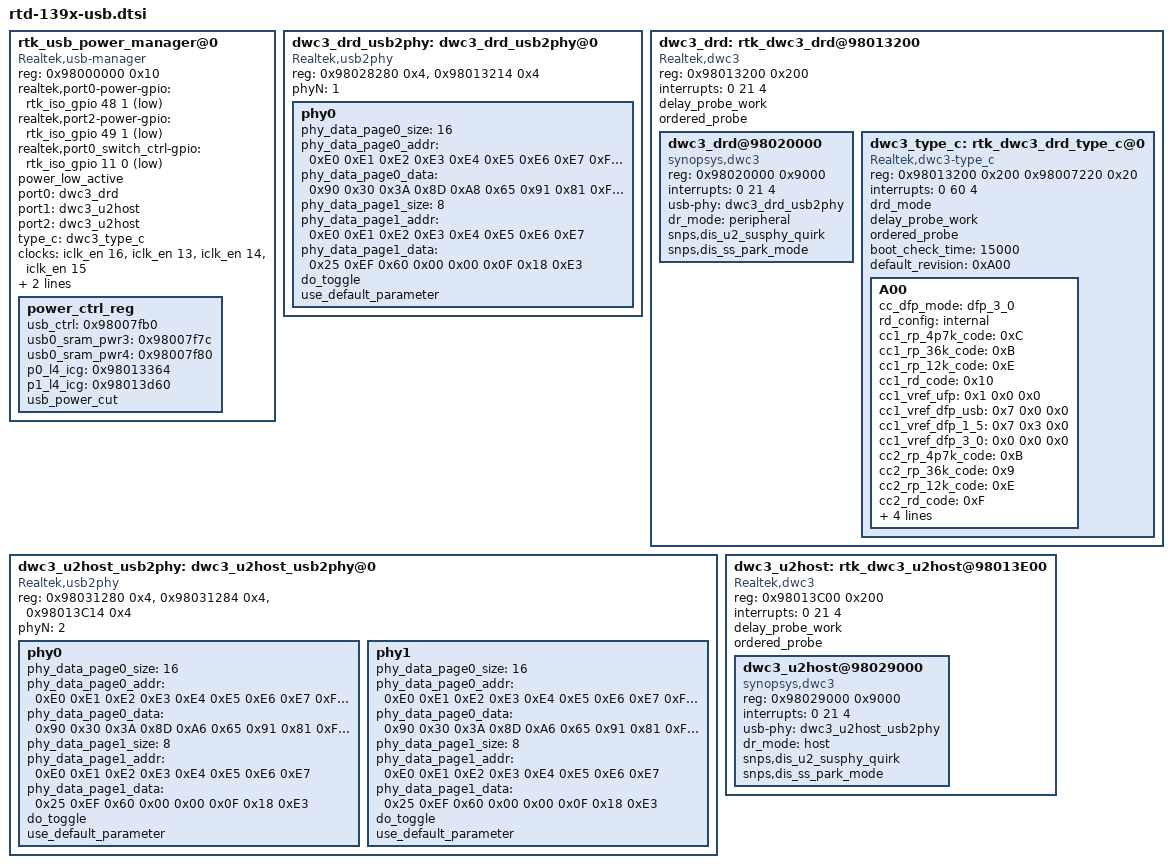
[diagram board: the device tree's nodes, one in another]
/*
 * realtek,type_c-power-gpio: TypeC power, output, default low
 * realtek,u2host-power-gpio: ehci and u2host power, output, default low
 * realtek,u3host-power-gpio: 1296 u3host power, output, default low
 *
 * usb_iso_mode: ISO mode is only port suspend (Default disable)
 * usb_power_cut: Non ISO mode and power cut (Default disable power cut)
 * Note if enable ISO mode, then power_cut will not effective
 */

	rtk_usb_power_manager@0 {
		compatible = "Realtek,usb-manager";
		reg = <0x98000000 0x10>;
		realtek,port0-power-gpio = <&rtk_iso_gpio 48 1 3>;
		//realtek,port1-power-gpio = <&rtk_iso_gpio 49 1 1>;
		realtek,port2-power-gpio = <&rtk_iso_gpio 49 1 3>;
		realtek,port0_switch_ctrl-gpio = <&rtk_iso_gpio 11 0 1>;
		power_low_active;

		port0 = <&dwc3_drd>;
		port1 = <&dwc3_u2host>;
		port2 = <&dwc3_u2host>;
		type_c = <&dwc3_type_c>;

		//usb_iso_mode;  /* ISO mode is only port suspend (Default disable) */
		//en_usb_storage_reprobe; /* To enable usb storage re-probe*/
		//rescue_usb; /* For rescue dtb use */

		clocks = <&iclk_en 16>, /* clk_en_usb */
			<&iclk_en 13>,  /* clk_en_usb_drd */
			<&iclk_en 14>,  /* clk_en_usb_host_0 */
			<&iclk_en 15>;  /* clk_en_usb_host_1 */
		clock-names = "clk_en_usb", /*clk_en_usb*/
			"clk_en_phy0_to_host", /*clk_en_usb_drd*/
			"clk_en_phy1_to_host", /*clk_en_usb_host_0*/
			"clk_en_phy2_to_host"; /*clk_en_usb_host_1*/

		resets =
			<&iasr 0x100>,
			<&irst 14>, /* rstn_usb_drd */
			<&irst 15>, /* rstn_usb_host */
			<&iasr 16>, /* rstn_usb_phy_0 */
			<&iasr 17>, /* rstn_usb_phy_1 */
			<&iasr 18>, /* rstn_usb_phy_2 */
			<&irst 19>, /* rstn_usb */
			<&irst 20>; /* rstn_type_c */

		reset-names = "apply",
			"usb_host0", /*rstn_usb_drd*/
			"usb_host1", /*rstn_usb_host*/
			"u2phy0", /*rstn_usb_phy_0*/
			"u2phy1", /*rstn_usb_phy_1*/
			"u2phy2", /*rstn_usb_phy_2*/
			"usb", /*rstn_usb*/
			"type_c"; /*rstn_type_c*/

		power_ctrl_reg {
			usb_ctrl = <0x98007fb0>;
			/* Port 0~2 */
			usb0_sram_pwr3 = <0x98007f7c>;
			usb0_sram_pwr4 = <0x98007f80>;

			/* l4_icg */
			p0_l4_icg = <0x98013364>;
			p1_l4_icg = <0x98013d60>;

			usb_power_cut; /* Non ISO mode and power cut (Default disable power cut) */
			               /* Note if enable ISO mode, then power_cut will not effective*/
		};

	};

	dwc3_drd_usb2phy: dwc3_drd_usb2phy@0 {
		compatible = "Realtek,usb2phy";
		reg = <0x98028280 0x4>, <0x98013214 0x4>;
		#address-cells = <1>;
		#size-cells = <1>;
		ranges;
		phyN = <1>;
		phy0 {
			phy_data_page0_size = <16>;
			phy_data_page0_addr = /bits/ 8
				<0xE0 0xE1 0xE2 0xE3 0xE4 0xE5 0xE6 0xE7 0xF0 0xF1
				0xF2 0xF3 0xF4 0xF5 0xF6 0xF7>;
			phy_data_page0_data = /bits/ 8
				<0x90 0x30 0x3A 0x8D 0xA8 0x65 0x91 0x81 0xFC 0x8C
				0x00 0x11 0x9B 0x81 0x00 0x02>;
			phy_data_page1_size = <8>;
			phy_data_page1_addr = /bits/ 8
				<0xE0 0xE1 0xE2 0xE3 0xE4 0xE5 0xE6 0xE7>;
			phy_data_page1_data = /bits/ 8
				<0x25 0xEF 0x60 0x00 0x00 0x0F 0x18 0xE3>;
			do_toggle;
			//check_efuse;
			use_default_parameter;
		};
	};

	dwc3_drd: rtk_dwc3_drd@98013200 {
		compatible = "Realtek,dwc3";
		reg = <0x98013200 0x200>;
		interrupts = <0 21 4>;
		#address-cells = <1>;
		#size-cells = <1>;
		ranges;
		delay_probe_work; //To delay probe work
		ordered_probe; // ordered probe in delay work
		status = "okay";

		dwc3_drd@98020000 {
			compatible = "synopsys,dwc3";
			reg = <0x98020000 0x9000>;
			interrupts = <0 21 4>;
			usb-phy = <&dwc3_drd_usb2phy>;
			dr_mode = "peripheral"; /*otg, host, peripheral*/
			//tx-fifo-resize;
			snps,dis_u2_susphy_quirk; // Add workaround for Usb3.0 hub suspend
			snps,dis_ss_park_mode; // disable usb3.0 park mode
		};

		dwc3_type_c: rtk_dwc3_drd_type_c@0 {
			compatible = "Realtek,dwc3-type_c";
			reg = <0x98013200 0x200 0x98007220 0x20>;
			interrupts = <0 60 4>;
			drd_mode;  /*depend on dwc3 dr_mode = "peripheral"*/
			//debug; /*to enable debug log*/
			delay_probe_work; /*To delay probe work*/
			ordered_probe; /*ordered probe in delay work*/
			boot_check_time = <15000>; /*ms (At boot Device switch Host time)*/

			default_revision = <0xA00>;
			A00 {
				cc_dfp_mode = "dfp_3_0"; /*dfp_3_0, dfp_1_5, dfp_usb*/
				rd_config = "internal"; /*internal, extrenal*/
				cc1_rp_4p7k_code = <0xC>;
				cc1_rp_36k_code = <0xB>;
				cc1_rp_12k_code = <0xE>;
				cc1_rd_code = <0x10>; /*for internal rd*/
				cc1_vref_ufp = /bits/ 8
					<0x1 0x0 0x0>; /*<1p23v,0p66v,0p2v>*/
				cc1_vref_dfp_usb = /bits/ 8
					<0x7 0x0 0x0>; /*<0_1p6v,0p2v,unused>*/
				cc1_vref_dfp_1_5 = /bits/ 8
					<0x7 0x3 0x0>; /*<1_1p6v,0p4v,0p2v>*/
				cc1_vref_dfp_3_0 = /bits/ 8
					<0x0 0x0 0x0>; /*<2p6v,0p8v,0p2v>*/
				cc2_rp_4p7k_code = <0xB>;
				cc2_rp_36k_code = <0x9>;
				cc2_rp_12k_code = <0xE>;
				cc2_rd_code = <0xF>; /*for internal rd*/
				cc2_vref_ufp = /bits/ 8
					<0x3 0x2 0x2>; /*<1p23v,0p66v,0p2v>*/
				cc2_vref_dfp_usb = /bits/ 8
					<0x7 0x2 0x0>; /*<0_1p6v,0p2v,unused>*/
				cc2_vref_dfp_1_5 = /bits/ 8
					<0x7 0x3 0x2>; /*<1_1p6v,0p4v,0p2v>*/
				cc2_vref_dfp_3_0 = /bits/ 8
					<0x1 0x3 0x2>; /*<2p6v,0p8v,0p2v>*/
			};
		};
	};

	dwc3_u2host_usb2phy: dwc3_u2host_usb2phy@0 {
		compatible = "Realtek,usb2phy";
		reg = <0x98031280 0x4>, <0x98031284 0x4>, <0x98013C14 0x4>;
		#address-cells = <1>;
		#size-cells = <1>;
		ranges;
		phyN = <2>;
		phy0 {
			phy_data_page0_size = <16>;
			phy_data_page0_addr = /bits/ 8
				<0xE0 0xE1 0xE2 0xE3 0xE4 0xE5 0xE6 0xE7 0xF0 0xF1
				0xF2 0xF3 0xF4 0xF5 0xF6 0xF7>;
			phy_data_page0_data = /bits/ 8
				<0x90 0x30 0x3A 0x8D 0xA6 0x65 0x91 0x81 0xFC 0x8C
				0x00 0x11 0x9B 0x81 0x00 0x02>;
			phy_data_page1_size = <8>;
			phy_data_page1_addr = /bits/ 8
				<0xE0 0xE1 0xE2 0xE3 0xE4 0xE5 0xE6 0xE7>;
			phy_data_page1_data = /bits/ 8
			<0x25 0xEF 0x60 0x00 0x00 0x0F 0x18 0xE3>;
			do_toggle;
			//check_efuse;
			use_default_parameter;
		};
		phy1 {
			phy_data_page0_size = <16>;
			phy_data_page0_addr = /bits/ 8
				<0xE0 0xE1 0xE2 0xE3 0xE4 0xE5 0xE6 0xE7 0xF0 0xF1
				0xF2 0xF3 0xF4 0xF5 0xF6 0xF7>;
			phy_data_page0_data = /bits/ 8
				<0x90 0x30 0x3A 0x8D 0xA6 0x65 0x91 0x81 0xFC 0x8C
				0x00 0x11 0x9B 0x81 0x00 0x02>;
			phy_data_page1_size = <8>;
			phy_data_page1_addr = /bits/ 8
				<0xE0 0xE1 0xE2 0xE3 0xE4 0xE5 0xE6 0xE7>;
			phy_data_page1_data = /bits/ 8
			<0x25 0xEF 0x60 0x00 0x00 0x0F 0x18 0xE3>;
			do_toggle;
			//check_efuse;
			use_default_parameter;
		};
	};

	dwc3_u2host: rtk_dwc3_u2host@98013E00 {
		compatible = "Realtek,dwc3";
		reg = <0x98013C00 0x200>;
		interrupts = <0 21 4>;
		#address-cells = <1>;
		#size-cells = <1>;
		ranges;
		delay_probe_work; //To delay probe work
		ordered_probe; // ordered probe in delay work
		status = "okay";

		dwc3_u2host@98029000 {
			compatible = "synopsys,dwc3";
			reg = <0x98029000 0x9000>;
			interrupts = <0 21 4>;
			usb-phy = <&dwc3_u2host_usb2phy>;
			dr_mode = "host"; /*only host*/
			//tx-fifo-resize;
			snps,dis_u2_susphy_quirk; // Add workaround for Usb3.0 hub suspend
			snps,dis_ss_park_mode; // disable usb3.0 park mode
		};
	};
